# CC430F5123 register map
Registers are 16-bit, read-write, reset 0x0 unless marked. A register's access mark holds for its fields unless they carry their own. Offsets are from the block's base; [hi:lo] are bit positions; {n}, {i} and the like mark numbered series.

## RC_RAM_Control_Module
Base 0x00000000
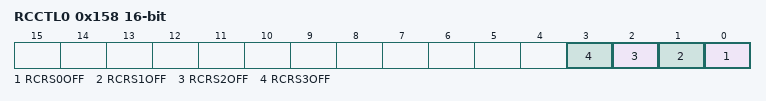
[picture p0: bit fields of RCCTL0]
0x158 RCCTL0 — Ram Controller Control Register
  [n] RCRS{n}OFF (n=0..3) — RAM Controller RAM Sector {n} Off

## Shared_Reference
Base 0x00000000
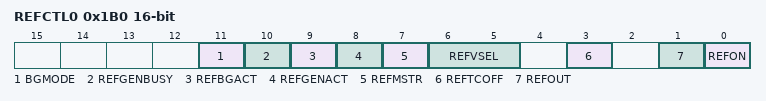
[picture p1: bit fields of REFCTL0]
0x1B0 REFCTL0 — REF Shared Reference control register 0
  [11] BGMODE — REF Bandgap mode
  [10] REFGENBUSY — REF Reference generator busy
  [9] REFBGACT — REF Reference bandgap active
  [8] REFGENACT — REF Reference generator active
  [7] REFMSTR — REF Master Control
  [6:5] REFVSEL — REF Reference Voltage Level Select Bit:0
    0=REF Reference Voltage Level Select 1.5V; 1=REF Reference Voltage Level Select 2.0V; 2=REF Reference Voltage Level Select 2.5V; 3=REF Reference Voltage Level Select 2.5V
  [3] REFTCOFF — REF Temp.Sensor off
  [1] REFOUT — REF Reference output Buffer On
  [0] REFON — REF Reference On

## SFR_Special_Function_Registers
Base 0x00000000
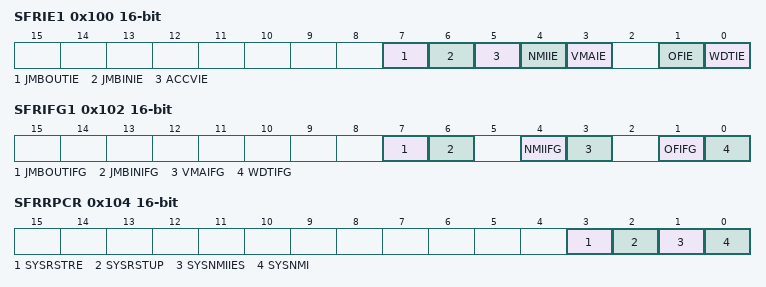
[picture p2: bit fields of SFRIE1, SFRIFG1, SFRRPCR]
0x100 SFRIE1 — Interrupt Enable 1
  [7] JMBOUTIE — JTAG Mail Box output Interrupt Enable
  [6] JMBINIE — JTAG Mail Box input Interrupt Enable
  [5] ACCVIE — Flash Access Violation Interrupt Enable
  [4] NMIIE — NMI Interrupt Enable
  [3] VMAIE — Vacant Memory Interrupt Enable
  [1] OFIE — Osc Fault Enable
  [0] WDTIE — WDT Interrupt Enable
0x102 SFRIFG1 — Interrupt Flag 1
  [7] JMBOUTIFG — JTAG Mail Box output Interrupt Flag
  [6] JMBINIFG — JTAG Mail Box input Interrupt Flag
  [4] NMIIFG — NMI Interrupt Flag
  [3] VMAIFG — Vacant Memory Interrupt Flag
  [1] OFIFG — Osc Fault Flag
  [0] WDTIFG — WDT Interrupt Flag
0x104 SFRRPCR — RESET Pin Control Register
  [3] SYSRSTRE — RESET Pin Resistor enable
  [2] SYSRSTUP — RESET Pin pull down/up select
  [1] SYSNMIIES — NMI edge select
  [0] SYSNMI — NMI select

## SYS_System_Module
Base 0x00000000
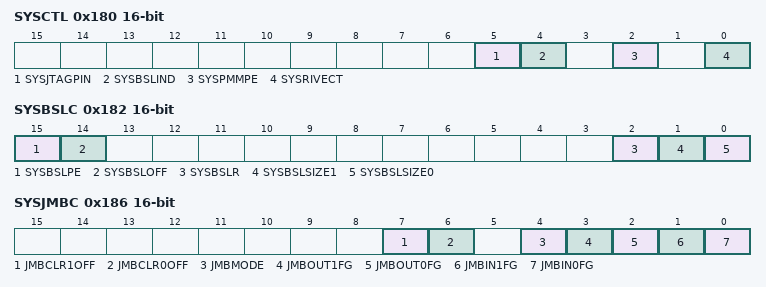
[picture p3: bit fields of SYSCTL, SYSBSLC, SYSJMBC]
0x180 SYSCTL — System control
  [5] SYSJTAGPIN — SYS - Dedicated JTAG pins enabled
  [4] SYSBSLIND — SYS - TCK/RST indication detected
  [2] SYSPMMPE — SYS - PMM access protect
  [0] SYSRIVECT — SYS - RAM based interrupt vectors
0x182 SYSBSLC — Boot strap configuration area
  [15] SYSBSLPE — SYS - BSL Memory protection enabled
  [14] SYSBSLOFF — SYS - BSL Memory disabled
  [2] SYSBSLR — SYS - RAM assigned to BSL
  [1] SYSBSLSIZE1 — SYS - BSL Protection Size 1
  [0] SYSBSLSIZE0 — SYS - BSL Protection Size 0
0x186 SYSJMBC — JTAG mailbox control
  [7] JMBCLR1OFF — SYS - Incoming JTAG Mailbox 1 Flag auto-clear disalbe
  [6] JMBCLR0OFF — SYS - Incoming JTAG Mailbox 0 Flag auto-clear disalbe
  [4] JMBMODE — SYS - JMB 16/32 Bit Mode
  [3] JMBOUT1FG — SYS - Outgoing JTAG Mailbox 1 Flag
  [2] JMBOUT0FG — SYS - Outgoing JTAG Mailbox 0 Flag
  [1] JMBIN1FG — SYS - Incoming JTAG Mailbox 1 Flag
  [0] JMBIN0FG — SYS - Incoming JTAG Mailbox 0 Flag
0x188 SYSJMBI0 — JTAG mailbox input 0
0x18A SYSJMBI1 — JTAG mailbox input 1
0x18C SYSJMBO0 — JTAG mailbox output 0
0x18E SYSJMBO1 — JTAG mailbox output 1
0x198 SYSBERRIV — Bus Error vector generator
0x19A SYSUNIV — User NMI vector generator
0x19C SYSSNIV — System NMI vector generator
0x19E SYSRSTIV — Reset vector generator

## Timer0_A5
Base 0x00000000
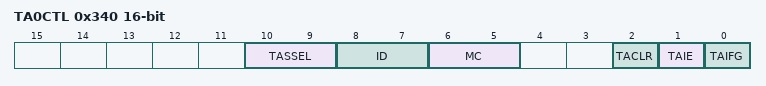
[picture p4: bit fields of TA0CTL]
0x340 TA0CTL — Timer0_A5 Control
  [10:9] TASSEL — Timer A clock source select 1
    0=Timer A clock source select: 0 - TACLK; 1=Timer A clock source select: 1 - ACLK; 2=Timer A clock source select: 2 - SMCLK; 3=Timer A clock source select: 3 - INCLK
  [8:7] ID — Timer A clock input divider 1
    0=Timer A input divider: 0 - /1; 1=Timer A input divider: 1 - /2; 2=Timer A input divider: 2 - /4; 3=Timer A input divider: 3 - /8
  [6:5] MC — Timer A mode control 1
    0=Timer A mode control: 0 - Stop; 1=Timer A mode control: 1 - Up to CCR0; 2=Timer A mode control: 2 - Continuous up; 3=Timer A mode control: 3 - Up/Down
  [2] TACLR — Timer A counter clear
  [1] TAIE — Timer A counter interrupt enable
  [0] TAIFG — Timer A counter interrupt flag
{0x342+2i} TA0CCTL{i} (i=0..4) — Timer0_A5 Capture/Compare Control {i}
  [16:15] CM — Capture mode 1
    0=Capture mode: 0 - disabled; 1=Capture mode: 1 - pos. edge; 2=Capture mode: 1 - neg. edge; 3=Capture mode: 1 - both edges
  [14:13] CCIS — Capture input select 1
    0=Capture input select: 0 - CCIxA; 1=Capture input select: 1 - CCIxB; 2=Capture input select: 2 - GND; 3=Capture input select: 3 - Vcc
  [11] SCS — Capture sychronize
  [10] SCCI — Latched capture signal (read)
  [8] CAP — Capture mode: 1 /Compare mode : 0
  [9:7] OUTMOD — Output mode 2
    0=PWM output mode: 0 - output only; 1=PWM output mode: 1 - set; 2=PWM output mode: 2 - PWM toggle/reset; 3=PWM output mode: 3 - PWM set/reset; 4=PWM output mode: 4 - toggle; 5=PWM output mode: 5 - Reset; 6=PWM output mode: 6 - PWM toggle/set; 7=PWM output mode: 7 - PWM reset/set
  [4] CCIE — Capture/compare interrupt enable
  [3] CCI — Capture input signal (read)
  [2] OUT — PWM Output signal if output mode 0
  [1] COV — Capture/compare overflow flag
  [0] CCIFG — Capture/compare interrupt flag
0x350 TA0R — Timer0_A5
{0x352+2i} TA0CCR{i} (i=0..4) — Timer0_A5 Capture/Compare {i}
0x360 TA0EX0 — Timer0_A5 Expansion Register 0
  [4:2] TAIDEX — Timer A Input divider expansion Bit: 0
    {v}=Timer A Input divider expansion : /{v+1} (v=0..7)
0x36E TA0IV — Timer0_A5 Interrupt Vector Word
